AUTOSAR XML (schema 4-3-0)
package /ComponentTypes
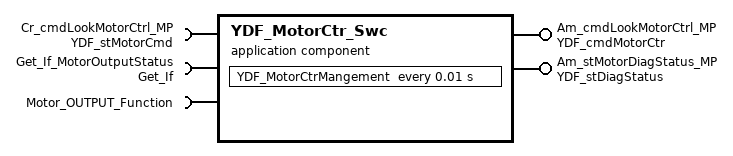
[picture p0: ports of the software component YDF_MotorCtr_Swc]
  application sw component type YDF_MotorCtr_Swc
    require port Cr_cmdLookMotorCtrl_MP: nonqueued-receiver-com-spec{data-element=MotorCmd, init-value=0}, required-interface=YDF_stMotorCmd
    provide port Am_cmdLookMotorCtrl_MP: nonqueued-sender-com-spec{data-element=MotorCtr, init-value=0}, provided-interface=YDF_cmdMotorCtr
    require port Get_If_MotorOutputStatus: required-interface=Get_If
      required-com-specs:
        Get_Ad_Result
        Get_io_inResult
        Get_BTS_OutResult
        Get_CAN_ActiveInf
        Icu_17_GtmCcu6_PWMIN_CH{1..4}
        Icu_17_GtmCcu6_PWMIN_PWMSCB1
        Icu_17_GtmCcu6_PWMIN_PWMSCB2
        Icu_17_GtmCcu6_PWMIN_LAMPSCB1
        Icu_17_GtmCcu6_PWMIN_LAMPSCB2
        Get_Bottom_Ver
        Get_SentData
        Get_Level_OutResult
        Get_PwmOrLevel_OutResult
        Get_Motor_OutResult
    provide port Am_stMotorDiagStatus_MP: nonqueued-sender-com-spec{data-element=DiagStatus, init-value=0}, provided-interface=YDF_stDiagStatus
    require port Motor_OUTPUT_Function: client-com-spec=App_Motor_OUTPUT_Function, required-interface=Motor_OUTPUT_Function
    behavior YDF_MotorCtr_Swc_InternalBehavior
      timing event TMT_YDF_MotorCtrMangement: start-on-event=YDF_MotorCtrMangement, period=0.01
      runnable YDF_MotorCtrMangement
        data-receive-point-by-arguments:
          access REC_Cr_cmdLookMotorCtrl_MP_MotorCmd: accessed-variable=Cr_cmdLookMotorCtrl_MP.MotorCmd
        data-send-points:
          access SEND_Am_cmdLookMotorCtrl_MP_MotorCtr: accessed-variable=Am_cmdLookMotorCtrl_MP.MotorCtr
          access SEND_Am_stMotorDiagStatus_MP_SignalStatus: accessed-variable=Am_stMotorDiagStatus_MP.DiagStatus
        sync call SC_Get_If_MotorOutputStatus_Get_Motor_OutResult: operation=Get_If_MotorOutputStatus.Get_Motor_OutResult
        sync call SC_Motor_OUTPUT_Function_App_Motor_OUTPUT_Function: operation=Motor_OUTPUT_Function.App_Motor_OUTPUT_Function
  swc implementation YDF_MotorCtr_Swc_Implementation: behavior=YDF_MotorCtr_Swc_InternalBehavior
